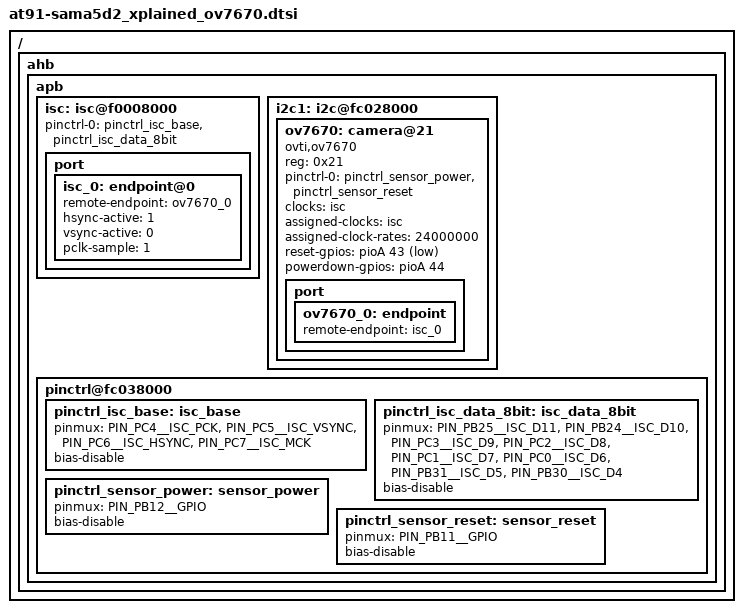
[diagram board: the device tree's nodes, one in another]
/*
 * at91-sama5d2_xplained_ov7670.dtsi - Device Tree file for OV7670 on SAMA5D2 Xplained board
 *
 *  Copyright (C) 2016 Atmel,
 *                2016 Nicolas Ferre <nicolas.ferre@atmel.com>
 *		  2016 Ludovic.Desroches <ludovic.desroches@atmel.com>
 *
 * This file is dual-licensed: you can use it either under the terms
 * of the GPL or the X11 license, at your option. Note that this dual
 * licensing only applies to this file, and not this project as a
 * whole.
 *
 *  a) This file is free software; you can redistribute it and/or
 *     modify it under the terms of the GNU General Public License as
 *     published by the Free Software Foundation; either version 2 of the
 *     License, or (at your option) any later version.
 *
 *     This file is distributed in the hope that it will be useful,
 *     but WITHOUT ANY WARRANTY; without even the implied warranty of
 *     MERCHANTABILITY or FITNESS FOR A PARTICULAR PURPOSE.  See the
 *     GNU General Public License for more details.
 *
 * Or, alternatively,
 *
 *  b) Permission is hereby granted, free of charge, to any person
 *     obtaining a copy of this software and associated documentation
 *     files (the "Software"), to deal in the Software without
 *     restriction, including without limitation the rights to use,
 *     copy, modify, merge, publish, distribute, sublicense, and/or
 *     sell copies of the Software, and to permit persons to whom the
 *     Software is furnished to do so, subject to the following
 *     conditions:
 *
 *     The above copyright notice and this permission notice shall be
 *     included in all copies or substantial portions of the Software.
 *
 *     THE SOFTWARE IS PROVIDED "AS IS", WITHOUT WARRANTY OF ANY KIND,
 *     EXPRESS OR IMPLIED, INCLUDING BUT NOT LIMITED TO THE WARRANTIES
 *     OF MERCHANTABILITY, FITNESS FOR A PARTICULAR PURPOSE AND
 *     NONINFRINGEMENT. IN NO EVENT SHALL THE AUTHORS OR COPYRIGHT
 *     HOLDERS BE LIABLE FOR ANY CLAIM, DAMAGES OR OTHER LIABILITY,
 *     WHETHER IN AN ACTION OF CONTRACT, TORT OR OTHERWISE, ARISING
 *     FROM, OUT OF OR IN CONNECTION WITH THE SOFTWARE OR THE USE OR
 *     OTHER DEALINGS IN THE SOFTWARE.
 */
#include "sama5d2-pinfunc.h"
#include <dt-bindings/gpio/gpio.h>

/ {
	ahb {
		apb {
			isc: isc@f0008000 {
				pinctrl-names = "default";
				pinctrl-0 = <&pinctrl_isc_base &pinctrl_isc_data_8bit>;
				status = "okay";

				port {
					isc_0: endpoint@0 {
						remote-endpoint = <&ov7670_0>;
						hsync-active = <1>;
						vsync-active = <0>;
						pclk-sample = <1>;
					};
				};
			};

			i2c1: i2c@fc028000 {
				ov7670: camera@21 {
					compatible = "ovti,ov7670";
					reg = <0x21>;
					pinctrl-names = "default";
					pinctrl-0 = <&pinctrl_sensor_power &pinctrl_sensor_reset>;
					clocks = <&isc>;
					clock-names = "xclk";
					assigned-clocks = <&isc>;
					assigned-clock-rates = <24000000>;
					reset-gpios = <&pioA 43 GPIO_ACTIVE_LOW>;
					powerdown-gpios = <&pioA 44 GPIO_ACTIVE_HIGH>;

					port {
						ov7670_0: endpoint {
							remote-endpoint = <&isc_0>;
						};
					};
				};
			};

			pinctrl@fc038000 {
				pinctrl_isc_base: isc_base {
					pinmux = <PIN_PC4__ISC_PCK>,
						 <PIN_PC5__ISC_VSYNC>,
						 <PIN_PC6__ISC_HSYNC>,
						 <PIN_PC7__ISC_MCK>;
					bias-disable;
				};

				pinctrl_isc_data_8bit: isc_data_8bit {
					pinmux = <PIN_PB25__ISC_D11>,
						 <PIN_PB24__ISC_D10>,
						 <PIN_PC3__ISC_D9>,
						 <PIN_PC2__ISC_D8>,
						 <PIN_PC1__ISC_D7>,
						 <PIN_PC0__ISC_D6>,
						 <PIN_PB31__ISC_D5>,
						 <PIN_PB30__ISC_D4>;
					bias-disable;
				};

				pinctrl_sensor_power: sensor_power {
					pinmux = <PIN_PB12__GPIO>;
					bias-disable;
				};

				pinctrl_sensor_reset: sensor_reset {
					pinmux = <PIN_PB11__GPIO>;
					bias-disable;
				};
			};
		};
	};
};
